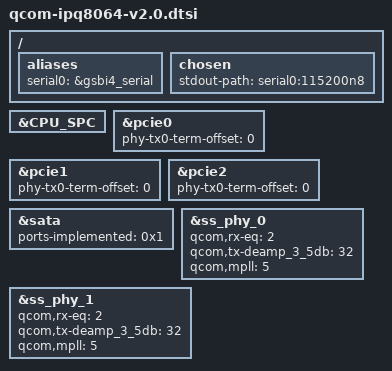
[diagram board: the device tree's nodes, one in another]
#include "qcom-ipq8064.dtsi"

/ {
	aliases {
		serial0 = &gsbi4_serial;
	};

	chosen {
		stdout-path = "serial0:115200n8";
	};
};

&CPU_SPC {
	status = "okay";
};

&pcie0 {
	phy-tx0-term-offset = <0>;
};

&pcie1 {
	phy-tx0-term-offset = <0>;
};

&pcie2 {
	phy-tx0-term-offset = <0>;
};

&sata {
	ports-implemented = <0x1>;
};

&ss_phy_0 {
	qcom,rx-eq = <2>;
	qcom,tx-deamp_3_5db = <32>;
	qcom,mpll = <5>;
};

&ss_phy_1 {
	qcom,rx-eq = <2>;
	qcom,tx-deamp_3_5db = <32>;
	qcom,mpll = <5>;
};
